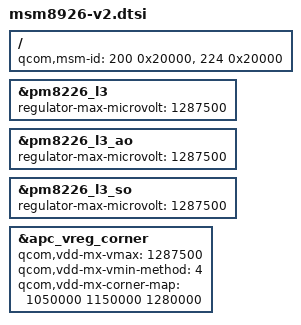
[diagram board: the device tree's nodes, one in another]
/* Copyright (c) 2013-2014, The Linux Foundation. All rights reserved.
 *
 * This program is free software; you can redistribute it and/or modify
 * it under the terms of the GNU General Public License version 2 and
 * only version 2 as published by the Free Software Foundation.
 *
 * This program is distributed in the hope that it will be useful,
 * but WITHOUT ANY WARRANTY; without even the implied warranty of
 * MERCHANTABILITY or FITNESS FOR A PARTICULAR PURPOSE.  See the
 * GNU General Public License for more details.
 */

#include "msm8926.dtsi"

/ {
	qcom,msm-id = <200 0x20000>,
		      <224 0x20000>;
};

&pm8226_l3 {
	regulator-max-microvolt = <1287500>;
};

&pm8226_l3_ao {
	regulator-max-microvolt = <1287500>;
};

&pm8226_l3_so {
	regulator-max-microvolt = <1287500>;
};

&apc_vreg_corner {
	/delete-property/ qcom,cpr-enable;
	qcom,vdd-mx-vmax = <1287500>;
	qcom,vdd-mx-vmin-method = <4>;
	qcom,vdd-mx-corner-map = <1050000 1150000 1280000>;
};
